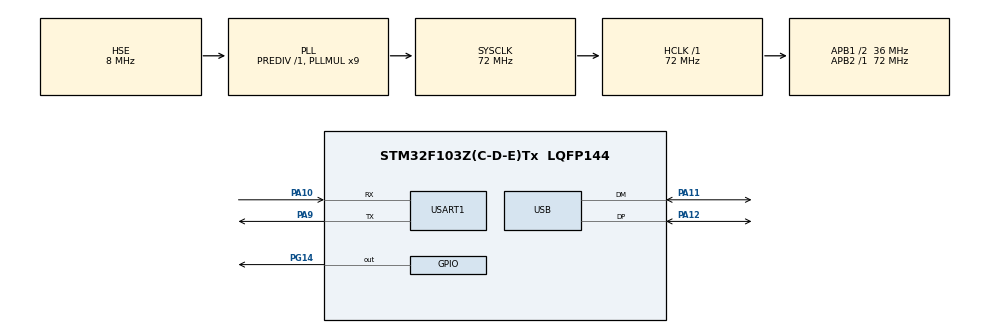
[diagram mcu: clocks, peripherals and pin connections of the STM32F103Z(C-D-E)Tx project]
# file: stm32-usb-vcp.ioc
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Mcu.Family=STM32F1
Mcu.Name=STM32F103Z(C-D-E)Tx
Mcu.Package=LQFP144
NVIC.PriorityGroup=NVIC_PRIORITYGROUP_4
NVIC.USB_HP_CAN1_TX_IRQn=true\:0\:0\:false\:false\:true\:true\:true\:true
NVIC.USB_LP_CAN1_RX0_IRQn=true\:0\:0\:false\:false\:true\:true\:true\:true
OSC_IN.Mode=HSE-External-Oscillator
OSC_IN.Signal=RCC_OSC_IN
OSC_OUT.Mode=HSE-External-Oscillator
OSC_OUT.Signal=RCC_OSC_OUT
PA10.Mode=Asynchronous
PA10.Signal=USART1_RX
PA11.Mode=Device
PA11.Signal=USB_DM
PA12.Mode=Device
PA12.Signal=USB_DP
PA13.Mode=Serial_Wire
PA13.Signal=SYS_JTMS-SWDIO
PA14.Mode=Serial_Wire
PA14.Signal=SYS_JTCK-SWCLK
PA9.Mode=Asynchronous
PA9.Signal=USART1_TX
PC14-OSC32_IN.Mode=LSE-External-Oscillator
PC14-OSC32_IN.Signal=RCC_OSC32_IN
PC15-OSC32_OUT.Mode=LSE-External-Oscillator
PC15-OSC32_OUT.Signal=RCC_OSC32_OUT
PG14.Signal=GPIO_Output
ProjectManager.HeapSize=0x200
ProjectManager.StackSize=0x400
ProjectManager.TargetToolchain=STM32CubeIDE
RCC.AHBFreq_Value=72000000
RCC.APB1CLKDivider=RCC_HCLK_DIV2
RCC.APB1Freq_Value=36000000
RCC.APB1TimFreq_Value=72000000
RCC.APB2Freq_Value=72000000
RCC.APB2TimFreq_Value=72000000
RCC.HCLKFreq_Value=72000000
RCC.PLLMUL=RCC_PLL_MUL9
RCC.PLLSourceVirtual=RCC_PLLSOURCE_HSE
RCC.RTCClockSelection=RCC_RTCCLKSOURCE_LSE
RCC.SYSCLKFreq_VALUE=72000000
RCC.SYSCLKSource=RCC_SYSCLKSOURCE_PLLCLK
RCC.USBFreq_Value=48000000
RCC.USBPrescaler=RCC_USBCLKSOURCE_PLL_DIV1_5
RTC.AutoPrediv=RTC_AUTO_1_SECOND
RTC.OutPut=RTC_OUTPUTSOURCE_CALIBCLOCK
USART1.VirtualMode=VM_ASYNC
VP_RTC_VS_RTC_Activate.Mode=RTC_Enabled
board=custom

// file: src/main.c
/* USER CODE BEGIN Header */
/**
  ******************************************************************************
  * @file           : main.c
  * @brief          : Main program body
  ******************************************************************************
  * @attention
  *
  * <h2><center>&copy; Copyright (c) 2021 STMicroelectronics.
  * All rights reserved.</center></h2>
  *
  * This software component is licensed by ST under Ultimate Liberty license
  * SLA0044, the "License"; You may not use this file except in compliance with
  * the License. You may obtain a copy of the License at:
  *                             www.st.com/SLA0044
  *
  ******************************************************************************
  */
/* USER CODE END Header */
#include "main.h"
#include "usart.h"
#include "usb_device.h"
#include "gpio.h"
#include "usbd_cdc_if.h"
#include "rtc_bkp.h"
#include<stdio.h>

/* USER CODE BEGIN PV */
uint32_t magic_value=0;
/* USER CODE END PV */

void SystemClock_Config(void);

/* USER CODE BEGIN 0 */
//复位后拉低usb引脚让电脑重新枚举，这样不需要断电。
void soft_reconnect_usb(){
    GPIO_InitTypeDef GPIO_InitStruct = {0};
    __HAL_RCC_GPIOA_CLK_ENABLE();
  HAL_GPIO_WritePin(GPIOA, GPIO_PIN_11|GPIO_PIN_12, GPIO_PIN_RESET);

  /*Configure GPIO pin : PG14 */
  GPIO_InitStruct.Pin = GPIO_PIN_11|GPIO_PIN_12;
  GPIO_InitStruct.Mode = GPIO_MODE_OUTPUT_PP;
  GPIO_InitStruct.Pull = GPIO_PULLDOWN;
  GPIO_InitStruct.Speed = GPIO_SPEED_FREQ_LOW;
  HAL_GPIO_Init(GPIOA, &GPIO_InitStruct);
  HAL_Delay(200);
}
/* USER CODE END 0 */

int main(void)
{

  /* MCU Configuration--------------------------------------------------------*/

  /* Reset of all peripherals, Initializes the Flash interface and the Systick. */
  HAL_Init();

  /* Configure the system clock */
  SystemClock_Config();
  soft_reconnect_usb();

  /* Initialize all configured peripherals */
  MX_GPIO_Init();
  MX_USART1_UART_Init();
  MX_RTC_Init();      //不要忘了系统时钟SystemClock_Config的配置

  // HAL_PWR_EnableBkUpAccess();
  // __HAL_RCC_BKP_CLK_ENABLE() ;
  MX_USB_DEVICE_Init();

  /* Infinite loop */
  /* USER CODE BEGIN WHILE */
  uint32_t preTick=uwTick;    //uwTick在systick中断中加1，也就是1ms加一次,也可以用  HAL_GetTick();

  HAL_RTCEx_BKUPWrite(&hrtc,RTC_BKP_DR1,MAGIC_VALUE&0xffff);
  HAL_RTCEx_BKUPWrite(&hrtc,RTC_BKP_DR2,(MAGIC_VALUE>>16)&0xffff);
  while (1)
  {
    /* USER CODE END WHILE */
    if (uwTick-preTick>=500){
      magic_value=0;
      preTick=uwTick;
      HAL_GPIO_TogglePin(GPIOG,GPIO_PIN_14);
      magic_value|=HAL_RTCEx_BKUPRead(&hrtc,RTC_BKP_DR1);
      magic_value|=HAL_RTCEx_BKUPRead(&hrtc,RTC_BKP_DR2)<<16;
      CDC_Transmit_FS((uint8_t *)&magic_value,4);
    }
    if (usb_rx_flag==1){
      usb_rx_flag=0;
      if(usb_rx_len>5){
        if (strncmp("rst_dfu",(char *)UserRxBufferFS,7)==0){
            HAL_RTCEx_BKUPWrite(&hrtc,RTC_BKP_DR3,RESET_TO_DFU&0xffff);
        }else if(strncmp("reset",(char *)UserRxBufferFS,5)==0){
            HAL_RTCEx_BKUPWrite(&hrtc,RTC_BKP_DR3,0);
        }
              CDC_Transmit_FS(UserRxBufferFS,usb_rx_len);
              HAL_GPIO_TogglePin(GPIOG,GPIO_PIN_14);
              HAL_Delay(100);
              HAL_GPIO_TogglePin(GPIOG,GPIO_PIN_14);
              HAL_Delay(100);
              HAL_GPIO_TogglePin(GPIOG,GPIO_PIN_14);
              HAL_Delay(100);
              HAL_GPIO_TogglePin(GPIOG,GPIO_PIN_14);
              HAL_Delay(100);
            HAL_NVIC_SystemReset();

      }

    }
  }
}

void SystemClock_Config(void)
{
  RCC_OscInitTypeDef RCC_OscInitStruct = {0};
  RCC_ClkInitTypeDef RCC_ClkInitStruct = {0};
  RCC_PeriphCLKInitTypeDef PeriphClkInit = {0};

  /** Initializes the RCC Oscillators according to the specified parameters
  * in the RCC_OscInitTypeDef structure.
  */
  RCC_OscInitStruct.OscillatorType = RCC_OSCILLATORTYPE_HSE|RCC_OSCILLATORTYPE_LSE;
  RCC_OscInitStruct.HSEState = RCC_HSE_ON;
  RCC_OscInitStruct.HSEPredivValue = RCC_HSE_PREDIV_DIV1;
  RCC_OscInitStruct.LSEState = RCC_LSE_ON;
  //RCC_OscInitStruct.HSIState = RCC_HSI_ON;
  RCC_OscInitStruct.PLL.PLLState = RCC_PLL_ON;
  RCC_OscInitStruct.PLL.PLLSource = RCC_PLLSOURCE_HSE;
  RCC_OscInitStruct.PLL.PLLMUL = RCC_PLL_MUL9;
  if (HAL_RCC_OscConfig(&RCC_OscInitStruct) != HAL_OK)
  {
    Error_Handler();
  }

  /** Initializes the CPU, AHB and APB buses clocks
  */
  RCC_ClkInitStruct.ClockType = RCC_CLOCKTYPE_HCLK|RCC_CLOCKTYPE_SYSCLK
                              |RCC_CLOCKTYPE_PCLK1|RCC_CLOCKTYPE_PCLK2;
  RCC_ClkInitStruct.SYSCLKSource = RCC_SYSCLKSOURCE_PLLCLK;
  RCC_ClkInitStruct.AHBCLKDivider = RCC_SYSCLK_DIV1;
  RCC_ClkInitStruct.APB1CLKDivider = RCC_HCLK_DIV2;
  RCC_ClkInitStruct.APB2CLKDivider = RCC_HCLK_DIV1;

  if (HAL_RCC_ClockConfig(&RCC_ClkInitStruct, FLASH_LATENCY_2) != HAL_OK)
  {
    Error_Handler();
  }
  PeriphClkInit.PeriphClockSelection = RCC_PERIPHCLK_RTC|RCC_PERIPHCLK_USB;
  PeriphClkInit.RTCClockSelection = RCC_RTCCLKSOURCE_LSE;
  PeriphClkInit.UsbClockSelection = RCC_USBCLKSOURCE_PLL_DIV1_5;
  if (HAL_RCCEx_PeriphCLKConfig(&PeriphClkInit) != HAL_OK)
  {
    Error_Handler();
  }
}

void Error_Handler(void)
{
  __disable_irq();
  while (1)
  {
  }
}
